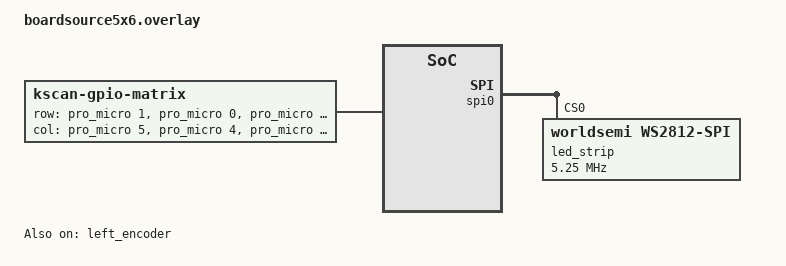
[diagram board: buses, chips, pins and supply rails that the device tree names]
/*
 * Copyright (c) 2021 The ZMK Contributors
 *
 * SPDX-License-Identifier: MIT
 */

#include <dt-bindings/zmk/matrix_transform.h>
#include "boardsource5x6.dtsi"
#include <dt-bindings/led/led.h>


&spi0 {

    led_strip: ws2812@0 {
        compatible = "worldsemi,ws2812-spi";

        /* SPI */
        reg = <0>;
        spi-max-frequency = <5250000>;

        /* WS2812 */
        chain-length = <10>; /* number of LEDs */
        spi-one-frame = <0x70>; /* make sure to configure this properly for your SOC */
        spi-zero-frame = <0x40>; /* make sure to configure this properly for your SOC */
        color-mapping = <LED_COLOR_ID_GREEN
        LED_COLOR_ID_RED
        LED_COLOR_ID_BLUE>;
    };
};

/ {
    chosen {
        zmk,underglow = &led_strip;
    };
};

/{
    chosen {
        zmk,kscan = &kscan0;
    };

    kscan0: kscan {
        compatible = "zmk,kscan-gpio-matrix";
        label = "KSCAN";
        diode-direction = "col2row";

        row-gpios
        = <&pro_micro 1 (GPIO_ACTIVE_HIGH | GPIO_PULL_DOWN)>
        , <&pro_micro 0 (GPIO_ACTIVE_HIGH | GPIO_PULL_DOWN)>
        , <&pro_micro 2 (GPIO_ACTIVE_HIGH | GPIO_PULL_DOWN)>
        , <&pro_micro 3 (GPIO_ACTIVE_HIGH | GPIO_PULL_DOWN)>
        , <&pro_micro 21 (GPIO_ACTIVE_HIGH | GPIO_PULL_DOWN)>
        ;

        col-gpios
        = <&pro_micro 5 GPIO_ACTIVE_HIGH>
        , <&pro_micro 4 GPIO_ACTIVE_HIGH>
        , <&pro_micro 9 GPIO_ACTIVE_HIGH>
        , <&pro_micro 8 GPIO_ACTIVE_HIGH>
        , <&pro_micro 6 GPIO_ACTIVE_HIGH>
        , <&pro_micro 7 GPIO_ACTIVE_HIGH>
        ;
    };
};

&left_encoder {
    status = "okay";
};

